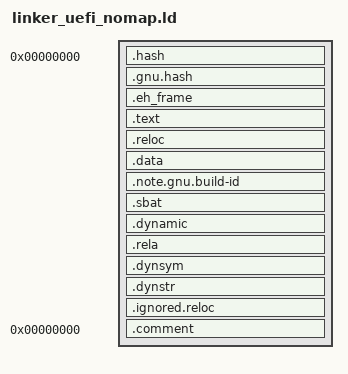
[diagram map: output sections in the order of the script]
/* The following code originates from gnu-efi */

OUTPUT_FORMAT("elf64-x86-64", "elf64-x86-64", "elf64-x86-64")
OUTPUT_ARCH(i386:x86-64)
ENTRY(_start)
SECTIONS
{
  . = 0;
  ImageBase = .;
  /* .hash and/or .gnu.hash MUST come first! */
  .hash : { *(.hash) }
  .gnu.hash : { *(.gnu.hash) }
  . = ALIGN(4096);
  .eh_frame :
  {
    *(.eh_frame)
  }
  . = ALIGN(4096);
  .text :
  {
   _text = .;
   *(.text)
   *(.text.*)
   *(.gnu.linkonce.t.*)
   . = ALIGN(16);
  }
  _etext = .;
  _text_size = . - _text;
  . = ALIGN(4096);
  .reloc :
  {
   *(.reloc)
  }
  . = ALIGN(4096);
  .data :
  {
   _data = .;
   *(.rodata*)
   *(.got.plt)
   *(.got)
   *(.data*)
   *(.sdata)
   /* the EFI loader doesn't seem to like a .bss section, so we stick
      it all into .data: */
   bss_begin = .;
   *(.sbss)
   *(.scommon)
   *(.dynbss)
   *(.bss)
   *(COMMON)
   bss_end = .;
   *(.rel.local)
   full_map = .;
  }
  .note.gnu.build-id : { *(.note.gnu.build-id) }

  _edata = .;
  _data_size = . - _etext;

  . = ALIGN(4096);
  .sbat :
  {
    _sbat = .;
    *(.sbat)
    *(.sbat.*)
  }
  _esbat = .;
  _sbat_size = . - _sbat;

  . = ALIGN(4096);
  .dynamic  : { *(.dynamic) }
  . = ALIGN(4096);
  .rela :
  {
    *(.rela.data*)
    *(.rela.got)
    *(.rela.stab)
  }
  . = ALIGN(4096);
  .dynsym   : { *(.dynsym) }
  . = ALIGN(4096);
  .dynstr   : { *(.dynstr) }
  . = ALIGN(4096);
  .ignored.reloc :
  {
    *(.rela.reloc)
    *(.eh_frame)
    *(.note.GNU-stack)
  }
  .comment 0 : { *(.comment) }
}
